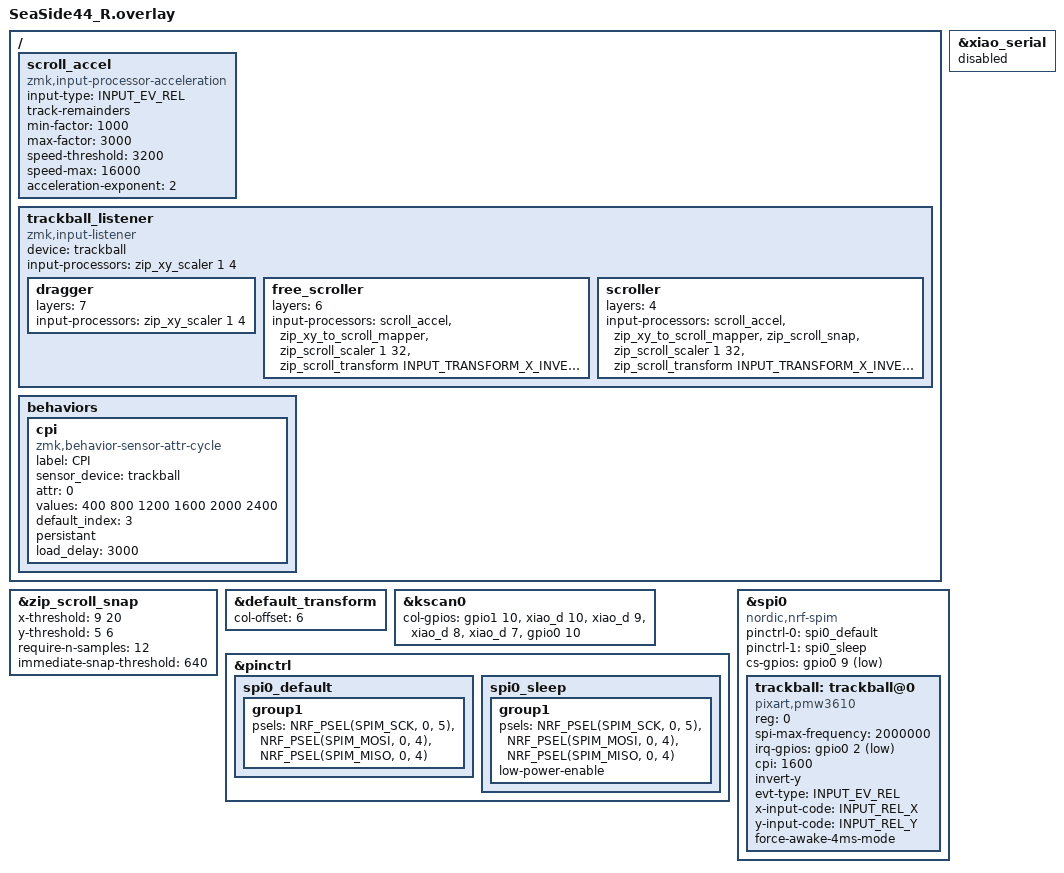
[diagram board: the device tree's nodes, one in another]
#include "SeaSide44.dtsi"
#include <input/processors.dtsi>
#include <zephyr/dt-bindings/input/input-event-codes.h>
#include <dt-bindings/zmk/input_transform.h>
#include <scroll-snap.dtsi>

&zip_scroll_snap {
    x-threshold = <9 20>;
    y-threshold = <5 6>;
    require-n-samples = <12>;
    immediate-snap-threshold = <640>;
};

&default_transform {
    col-offset = <6>;
};

/* キーマトリクスの設定 */
// 上が外側、下が内側カラムcol番号と実際の配置が直感と逆になってる
&kscan0 {
        col-gpios
            = <&gpio1 10 GPIO_ACTIVE_HIGH>
            , <&xiao_d 10 GPIO_ACTIVE_HIGH>
            , <&xiao_d 9 GPIO_ACTIVE_HIGH> 
            , <&xiao_d 8 GPIO_ACTIVE_HIGH> 
            , <&xiao_d 7 GPIO_ACTIVE_HIGH> 
            , <&gpio0 10 GPIO_ACTIVE_HIGH>
            ;
};

/* Trackball のリスナー */ 
/ {
    scroll_accel: scroll_accel {
        compatible = "zmk,input-processor-acceleration";
        #input-processor-cells = <0>;
        input-type = <INPUT_EV_REL>;
        track-remainders;
        min-factor = <1000>;
        max-factor = <3000>;
        speed-threshold = <3200>;
        speed-max = <16000>;
        acceleration-exponent = <2>;
    };

    trackball_listener {
        compatible = "zmk,input-listener";
        device = <&trackball>;
        input-processors = <&zip_xy_scaler 1 4>;

        dragger {
            layers = <7>;
            input-processors = <&zip_xy_scaler 1 4>;
        };

        free_scroller {
            layers = <6>;
            input-processors = <&scroll_accel &zip_xy_to_scroll_mapper &zip_scroll_scaler 1 32 &zip_scroll_transform INPUT_TRANSFORM_X_INVERT>;
        };

        scroller {
            layers = <4>;
            input-processors = <&scroll_accel &zip_xy_to_scroll_mapper &zip_scroll_snap &zip_scroll_scaler 1 32 &zip_scroll_transform INPUT_TRANSFORM_X_INVERT>;
        };
    };

    behaviors {
        cpi: cpi {
            compatible = "zmk,behavior-sensor-attr-cycle";
            label = "CPI";
            #binding-cells = <1>;
            sensor_device = <&trackball>;
            attr = <0>;
            values = <400 800 1200 1600 2000 2400>;
            default_index = <3>;
            persistant;
            load_delay = <3000>;
        };
    };
};

/* SPI 設定 */
&pinctrl {
    spi0_default: spi0_default {
        group1 {
            psels = <NRF_PSEL(SPIM_SCK, 0, 5)>,
                <NRF_PSEL(SPIM_MOSI, 0, 4)>,
                <NRF_PSEL(SPIM_MISO, 0, 4)>;
        };
    };

    spi0_sleep: spi0_sleep {
        group1 {
            psels = <NRF_PSEL(SPIM_SCK, 0, 5)>,
                <NRF_PSEL(SPIM_MOSI, 0, 4)>,
                <NRF_PSEL(SPIM_MISO, 0, 4)>;
            low-power-enable;
        };
    };
};

/* シリアルを無効化 */
&xiao_serial { status = "disabled"; };

/* SPI デバイス (トラックボール) */
&spi0 {
    status = "okay";
    compatible = "nordic,nrf-spim";
    pinctrl-0 = <&spi0_default>;
    pinctrl-1 = <&spi0_sleep>;
    pinctrl-names = "default", "sleep";
    cs-gpios = <&gpio0 9 GPIO_ACTIVE_LOW>;

    trackball: trackball@0 {
        status = "okay";
        compatible = "pixart,pmw3610";
        reg = <0>;
        spi-max-frequency = <2000000>;
        irq-gpios = <&gpio0 2 (GPIO_ACTIVE_LOW | GPIO_PULL_UP)>;
        // automouse-layer = <4>; //ここをコメントアウトするとオートマウスレイヤーがオフになる
        // scroll-layers = <5>;
        cpi = <1600>;
        invert-y;
        evt-type = <INPUT_EV_REL>;
        x-input-code = <INPUT_REL_X>;
        y-input-code = <INPUT_REL_Y>;
        force-awake-4ms-mode;
    };
};

